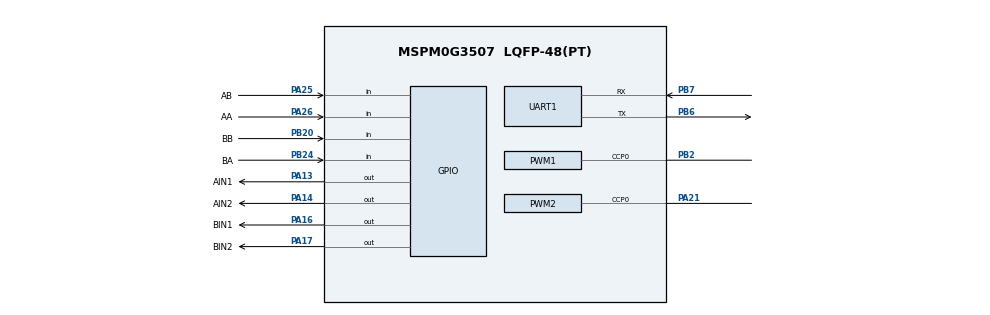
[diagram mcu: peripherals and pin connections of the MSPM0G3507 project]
//@cliArgs --device "MSPM0G350X" --package "LQFP-48(PT)" --part "Default"
//@v2CliArgs --device "MSPM0G3507" --package "LQFP-48(PT)"

/**
 * Import the modules used in this configuration.
 */
const UART    = scripting.addModule("/ti/driverlib/UART", {}, false);
const UART1   = UART.addInstance();
const GPIO    = scripting.addModule("/ti/driverlib/GPIO", {}, false);
const GPIO1   = GPIO.addInstance();
const GPIO2   = GPIO.addInstance();
const GPIO3   = GPIO.addInstance();
const PWM     = scripting.addModule("/ti/driverlib/PWM", {}, false);
const PWM1    = PWM.addInstance();
const PWM2    = PWM.addInstance();
const TIMER    = scripting.addModule("/ti/driverlib/TIMER", {}, false);
const TIMER1   = TIMER.addInstance();
const SYSCTL  = scripting.addModule("/ti/driverlib/SYSCTL");

/**
 * Write custom configuration values to the imported modules.
 */

/* ---------- UART (Debug Print) ---------- */
UART1.$name                    = "UART_DEBUG";
UART1.enableFIFO               = true;
UART1.targetBaudRate           = 115200;
UART1.enableMajorityVoting     = true;
UART1.peripheral.$assign       = "UART1";
UART1.peripheral.rxPin.$assign = "PB7";
UART1.peripheral.txPin.$assign = "PB6";
UART1.txPinConfig.$name        = "ti_driverlib_gpio_GPIOPinGeneric0";
UART1.rxPinConfig.$name        = "ti_driverlib_gpio_GPIOPinGeneric1";

/* ---------- GPIO: TB6612 Motor Control ---------- */
GPIO1.$name                         = "DC_MOTOR";
GPIO1.associatedPins.create(4);
GPIO1.associatedPins[0].$name       = "AIN1";
GPIO1.associatedPins[0].pin.$assign = "PA13";
GPIO1.associatedPins[1].$name       = "AIN2";
GPIO1.associatedPins[1].pin.$assign = "PA14";
GPIO1.associatedPins[2].$name       = "BIN1";
GPIO1.associatedPins[2].pin.$assign = "PA16";
GPIO1.associatedPins[3].$name       = "BIN2";
GPIO1.associatedPins[3].pin.$assign = "PA17";

/* ---------- PWM: Motor A (PWMA → PB2) ---------- */
PWM1.$name                   = "PWMA";
PWM1.ccIndex                 = [0];
PWM1.timerCount              = 4000;
PWM1.pwmMode                 = "EDGE_ALIGN_UP";
PWM1.timerStartTimer         = true;
PWM1.PWM_CHANNEL_0.$name     = "ti_driverlib_pwm_PWMTimerCC0";
PWM1.peripheral.ccp0Pin.$assign = "PB2";
PWM1.ccp0PinConfig.direction = scripting.forceWrite("OUTPUT");
PWM1.ccp0PinConfig.hideOutputInversion  = scripting.forceWrite(false);
PWM1.ccp0PinConfig.onlyInternalResistor = scripting.forceWrite(false);
PWM1.ccp0PinConfig.passedPeripheralType = scripting.forceWrite("Digital");
PWM1.ccp0PinConfig.$name     = "ti_driverlib_gpio_GPIOPinGeneric2";

/* ---------- PWM: Motor B (PWMB → PA21) ---------- */
PWM2.$name                   = "PWMB";
PWM2.ccIndex                 = [0];
PWM2.timerCount              = 4000;
PWM2.pwmMode                 = "EDGE_ALIGN_UP";
PWM2.timerStartTimer         = true;
PWM2.PWM_CHANNEL_0.$name     = "ti_driverlib_pwm_PWMTimerCC1";
PWM2.peripheral.ccp0Pin.$assign = "PA21";
PWM2.ccp0PinConfig.direction = scripting.forceWrite("OUTPUT");
PWM2.ccp0PinConfig.hideOutputInversion  = scripting.forceWrite(false);
PWM2.ccp0PinConfig.onlyInternalResistor = scripting.forceWrite(false);
PWM2.ccp0PinConfig.passedPeripheralType = scripting.forceWrite("Digital");
PWM2.ccp0PinConfig.$name     = "ti_driverlib_gpio_GPIOPinGeneric3";

/* ---------- GPIO: Encoder Motor A (PA26=A phase, PA25=B phase) ---------- */
GPIO2.$name                              = "ENCODER_A";
GPIO2.associatedPins.create(2);
GPIO2.associatedPins[0].$name            = "AA";
GPIO2.associatedPins[0].direction        = "INPUT";
GPIO2.associatedPins[0].interruptEn      = true;
GPIO2.associatedPins[0].polarity         = "RISE_FALL";
GPIO2.associatedPins[0].internalResistor = "PULL_UP";
GPIO2.associatedPins[0].pin.$assign      = "PA26";
GPIO2.associatedPins[1].$name            = "AB";
GPIO2.associatedPins[1].direction        = "INPUT";
GPIO2.associatedPins[1].internalResistor = "PULL_UP";
GPIO2.associatedPins[1].pin.$assign      = "PA25";

/* ---------- GPIO: Encoder Motor B (PB24=A phase, PB20=B phase) ---------- */
GPIO3.$name                              = "ENCODER_B";
GPIO3.associatedPins.create(2);
GPIO3.associatedPins[0].$name            = "BA";
GPIO3.associatedPins[0].direction        = "INPUT";
GPIO3.associatedPins[0].interruptEn      = true;
GPIO3.associatedPins[0].polarity         = "RISE_FALL";
GPIO3.associatedPins[0].internalResistor = "PULL_UP";
GPIO3.associatedPins[0].pin.$assign      = "PB24";
GPIO3.associatedPins[1].$name            = "BB";
GPIO3.associatedPins[1].direction        = "INPUT";
GPIO3.associatedPins[1].internalResistor = "PULL_UP";
GPIO3.associatedPins[1].pin.$assign      = "PB20";

/* ---------- TIMER: Speed Measurement (50ms period) ---------- */
TIMER1.$name              = "MOTOR_SPEED";
TIMER1.timerMode          = "PERIODIC_UP";
TIMER1.timerPeriod        = "50ms";
TIMER1.timerClkPrescale   = 100;
TIMER1.interrupts         = ["LOAD"];
TIMER1.peripheral.$assign = "TIMG0";

const Board = scripting.addModule("/ti/driverlib/Board", {}, false);

SYSCTL.forceDefaultClkConfig = true;
